AUTOSAR XML (schema 4-2-2)
package /AUTOLIV/SoftwareComponents/AdcIf
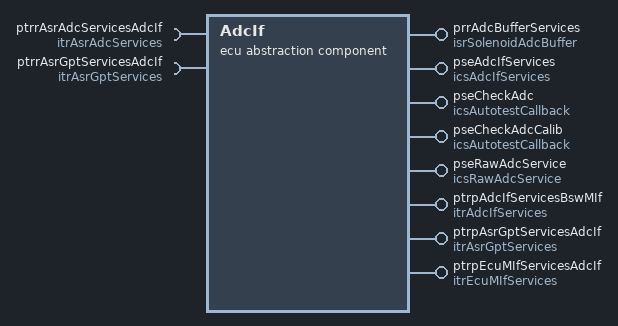
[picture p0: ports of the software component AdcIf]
  ecu abstraction sw component type AdcIf: category=MCAL_IO_Drivers
    8 x provide port:
      prrAdcBufferServices: provided-interface=isrSolenoidAdcBuffer  # # Architecture Element ID - ARCH_SW_AdcIf_prrAdcBufferServices_AdcIf_GPTOnTimer_Expiration # Description - The interface shall provide the {Raw value} from AdcIf in LSB in order to determine if solenoid has been confirmed or not. - In order to read from coresponding positions, the interface shall also carry the last written position. # Data Flow ## Outputs - {Raw value} # Linked Runnable - AdcIf_GPTOnTimer_Expiration ISR #Traceability
        provided-com-specs:
          data-element=aau16HistoricalAdcSamples, uses-end-to-end-protection=0, init-value=[aau16HistoricalAdcSamplesType_Appl_0:6 x 0, aau16HistoricalAdcSamplesType_Appl_1:6 x 0, aau16HistoricalAdcSamplesType_Appl_2:6 x 0, aau16HistoricalAdcSamplesType_Appl_3:6 x 0, aau16HistoricalAdcSamplesType_Appl_4:6 x 0, aau16HistoricalAdcSamplesType_Appl_5:6 x 0]
          data-element=u8HistoricalAdcSampleIndex, uses-end-to-end-protection=0, init-value=0
      pseAdcIfServices: provided-interface=icsAdcIfServices  # # Architecture Element ID ARCH_SW_AdcIf_pseAdcIfServices_AdcIf_StartConversion # Description - The AdcIf_StartConversion shall be called in order to start GPT timer for ADC sampling operations # Data Flow ## Inputs: - None ## Outputs: - None # Linked Runnable - AdcIf_StartConversion # Traceability #------------------------------------------------------------------------------------------------------------------------------------------------------- # Architecture Element ID ARCH_SW_AdcIf_pseAdcIfServices_AdcIf_StopConversion # Description - The AdcIf_StopConversion shall be called in order to stop GPT timer for ADC sampling operations # Data Flow ## Inputs: - None ## Outputs: - None # Linked Runnable - AdcIf_StopConversion # Traceability #------------------------------------------------------------------------------------------------------------------------------------------------------- # Architecture Element ID ARCH_SW_AdcIf_pseAdcIfServices_AdcIf_WaitForConversion # Description - The AdcIf_WaitForConversion shall be called in order to wait for ADC pheripheral to finish sampling operations. # Data Flow ## Inputs: - None ## Outputs: - None # Linked Runnable - AdcIf_WaitForConversion # Traceability
        provided-com-specs:
          operation=StartConversion, queue-length=1
          operation=StopConversion, queue-length=1
          operation=WaitForConversion, queue-length=1
      pseCheckAdc: server-com-spec{operation=AutotestCallback, queue-length=1}, provided-interface=icsAutotestCallback  # # Architecture Element ID ARCH_SW_AdcIf_pseCheckAdc # Description - The autotest shall read the low and high voltage refference for the ADC peripheral via the {AdcIf_runGetChannelValue} runnable and will compare them with thresholds stored in the NvM memory({NVP_u16ADCLowVoltageThrs}, {NVP_u16ADCHighVoltageThrs}). - Comparison shall be done in mV. - If {Adc Channel V Ref High} is lower than {NVP_u16ADCHighVoltageThrs} then the {Autotest Result} must be NOK. - If {Adc Channel V Ref Low} is greater than {NVP_u16ADCHighVoltageThrs} then the {Autotest Result} must be NOK. - If the channel references are within the threshold then the {Autotest Result} must be OK. # Data Flow ## Inputs: - {NVP_u16ADCLowVoltageThrs} - {NVP_u16ADCHighVoltageThrs} - {Adc Channel V Ref High} (Converted in mV) - {Adc Channel V Ref Low} (Converted in mV) ## Outputs - {Autotest Result} - Can be one of the following values: OK,NOK,NOT DECIDED # Linked Runnable - AdcIf_Autotest_CheckAdc # Traceability DOM_eCS_TF_H_129, DOM_eCS_TF_H_121, DOM_eCS_TF_H_220, DOM_eCS_TF_H_125, DOM_eCS_TF_H_221, DOM_eCS_TF_H_126, DOM_eCS_TF_H_222, DOM_eCS_TF_H_124, FUSA_SM_S32K1XXSM_302, FUSA_SM_S32K1XXSM_849, FUSA_SM_S32K1XXSM_850, FUSA_SM_S32K1XXSM_926
      pseCheckAdcCalib: server-com-spec{operation=AutotestCallback, queue-length=1}, provided-interface=icsAutotestCallback  # # Architecture Element ID ARCH_SW_AdcIf_pseCheckAdcCalib # Description - The autotest shall read the calibration status provided by the AdcIf_Calib runnable(OK or NOK) and will output the result. - If {Calibration Status for Group 0} or {Calibration Status for Group 1} are NOK then the {Autotest Result} must be NOK. - If the calibration status for both channels is OK then the {Autotest Result} must be OK # Data Flow ## Inputs - {Calibration Status for Group 0} - {Calibration Status for Group 1} ## Outputs - {Autotest Result} - Can be one of the following values: OK,NOK,NOT DECIDED # Linked Runnable - AdcIf_Autotest_CheckAdcCalib #Traceability DOM_eCS_TF_H_141, DOM_eCS_TF_H_142, DOM_eCS_TF_H_140
      pseRawAdcService: server-com-spec{operation=getChannelValue, queue-length=1}, provided-interface=icsRawAdcService  # # Architecture Element ID ARCH_SW_AdcIf_pseRawAdcService # Description - The getChannelValue operation shall return the lsb value on the {LSB value for the Channel Id} output parameter for the specified channel on the {Channel Id} input parameter. - The LSB value for the channel will be stored in an internal buffer in the AdcIf module. - The runnable shall read the lsb value for the following channels: - PTC sensor: PTC6 uC pin - KL30 (V_BAT): PTA2 uC pin - MAG_V_1: PTB13 uC pin - MAG_V_2: PTB12 uC pin - MAG_V_3: PTD4 uC pin - MAG_V_4: PTD3 uC pin - MAG_V_5: PTA6 uC pin - MAG_V_6: PTA7 uC pin - ADC REF High - ADC REF Low - MCU BAND GAP: internal uC channel - MCU Temp sensor: internal uC channel - Wake 1: PTA0 uC pin - Wake 2: PTA1 uC pin # Data Flow ## Inputs: - {Channel Id} ## Outputs: - {LSB value for the Channel Id} # Linked Runnable - AdcIf_runGetChannelValue # Traceability
      ptrpAdcIfServicesBswMIf: provided-interface=itrAdcIfServices  # # Architecture Element ID ARCH_SW_AdcIf_ptrpAdcIfServicesBswMIf_AdcIf_runInit # Description - The AdcIf_runInit runnable shall be called during the initialization in the BswM_OnStartupTwoA runnable # Data Flow # Linked Runnable - AdcIf_runInit # Traceability #------------------------------------------------------------------------------------------------------------------------------------------------------- # Architecture Element ID ARCH_SW_AdcIf_ptrpAdcIfServicesBswMIf_AdcIf_runDeInit # Description - The AdcIf_runDeInit runnable shall be called during the de-initialization in the BswM_OnGoOffOneA runnable # Data Flow # Linked Runnable - AdcIf_runDeInit # Traceability
      ptrpAsrGptServicesAdcIf: provided-interface=itrAsrGptServices  # # Architecture Element ID ARCH_SW_AdcIf_ptrpAsrGptServicesAdcIf # Description - The AdcIf_GPTOnTimer_Expiration runnable shall be called when the Gpt timer expires via the Gpt_InitChannelPB_TDK_4G runnable # Data Flow # Linked Runnable - AdcIf_GPTOnTimer_Expiration # Traceability FUSA_SM_S32K1XXSM_854
      ptrpEcuMIfServicesAdcIf: provided-interface=itrEcuMIfServices  # # Architecture Element ID ARCH_SW_AdcIf_ptrpEcuMIfServicesAdcIf # Description - The AdcIf_Calib runnable shall be called during the initialization in the EcuM_DefaultInitListOne runnable # Data Flow #Linked Runnable - AdcIf_Calib # Traceability
    require port ptrrAsrAdcServicesAdcIf: required-interface=itrAsrAdcServices  # # Architecture Element ID ARCH_SW_AdcIf_ptrrAsrAdcServices_Adc_StartGroupConversion_AdcIf_runInit # Description - The Adc_StartGroupConversion runnable shall be called in the AdcIf_runInit runnable in order to start the first conversion # Data Flow # Linked Runnable - AdcIf_runInit #Traceability #------------------------------------------------------------------------------------------------------------------------------------------------------- # Architecture Element ID ARCH_SW_AdcIf_ptrrAsrAdcServicesAdcIf_Adc_StartGroupConversion_AdcIf_GPTOnTimer_Expiration # Description - The Adc_StartGroupConversion runnable shall be called in the AdcIf_GPTOnTimer_Expiration runnable in order to start the periodic conversion # Data Flow # Linked Runnable - AdcIf_GPTOnTimer_Expiration #Traceability #------------------------------------------------------------------------------------------------------------------------------------------------------- # Architecture Element ID ARCH_SW_AdcIf_ptrrAsrAdcServicesAdcIf_Adc_Calibrate_AdcIf_Calib # Description - The Adc_Calibrate runnable shall be called in the AdcIf_Calib runnable in order to calibrate the Adc hw units according to the S32k datasheet - The runnable shall store the calibration status for both hw units # Data Flow ## Outputs - {Calibration Status for Group 0} - {Calibration Status for Group 1} # Linked Runnable - AdcIf_Calib #Traceability #------------------------------------------------------------------------------------------------------------------------------------------------------- # Architecture Element ID ARCH_SW_AdcIf_ptrrAsrAdcServicesAdcIf_Adc_StopGroupConversion_AdcIf_runDeInit # Description - The Adc_StopGroupConversion runnable shall be called in the AdcIf_runDeInit runnable in order to stop the group conversion before ECU shutdown # Data Flow # Linked Runnable - AdcIf_runDeInit #Traceability #------------------------------------------------------------------------------------------------------------------------------------------------------- # Architecture Element ID ARCH_SW_AdcIf_ptrrAsrAdcServicesAdcIf_Adc_ReadGroup_AdcIf_GPTOnTimer_Expiration # Description - The Adc_ReadGroup runnable shall be called in the AdcIf_GPTOnTimer_Expiration runnable in order to get the lsb value from the Adc groups # Data Flow # Linked Runnable - AdcIf_GPTOnTimer_Expiration #Traceability #------------------------------------------------------------------------------------------------------------------------------------------------------- # Architecture Element ID ARCH_SW_AdcIf_ptrrAsrAdcServicesAdcIf_Adc_ReadGroup_AdcIf_WaitForConversion # Description - The Adc_ReadGroup runnable shall be called in the AdcIf_WaitForConversion runnable in order to get the lsb value from the Adc groups # Data Flow # Linked Runnable - AdcIf_WaitForConversion #Traceability
    require port ptrrAsrGptServicesAdcIf: required-interface=itrAsrGptServices  # ARCH_SW_AdcIf_ptrrAsrGptServicesAdcIf_Gpt_StopTimer_AdcIf_StopConversion # Description - The Gpt_StopTimer runnable shall be called in the AdcIf_StopConversion runnable in order to stop the timer that trigger the Adc conversion # Data Flow # Linked Runnable - AdcIf_StopConversion # Traceability #------------------------------------------------------------------------------------------------------------------------------------------------------- ARCH_SW_AdcIf_ptrrAsrGptServicesAdcIf_Gpt_StartTimer_AdcIf_StartConversion # Description - The Gpt_StartTimer runnable shall be called in the AdcIf_StartConversion runnable in order to start the timer that will trigger the Adc conversion # Data Flow # Linked Runnable - AdcIf_StartConversion # Traceability #------------------------------------------------------------------------------------------------------------------------------------------------------- # Architecture Element ID ARCH_SW_AdcIf_ptrrAsrGptServicesAdcIf_Gpt_Init_AdcIf_runInit # Description - The Gpt_Init runnable shall be called in the AdcIf_runInit runnable in order to initialize the Gpt component # Data Flow # Linked Runnable - AdcIf_runInit # Traceability #------------------------------------------------------------------------------------------------------------------------------------------------------- # Architecture Element ID ARCH_SW_AdcIf_ptrrAsrGptServicesAdcIf_Gpt_StartTimer_AdcIf_runInit # Description - The Gpt_StartTimer runnable shall be called in the AdcIf_runInit runnable in order to start the timer that will trigger the Adc conversion # Data Flow # Linked Runnable - AdcIf_runInit # Traceability #------------------------------------------------------------------------------------------------------------------------------------------------------- # Architecture Element ID ARCH_SW_AdcIf_ptrrAsrGptServicesAdcIf_Gpt_EnableNotification_AdcIf_runInit # Description - The Gpt_EnableNotification runnable shall be called in the AdcIf_runInit runnable in order to enable the notification on the timer expiration event # Data Flow # Linked Runnable - AdcIf_runInit # Traceability
